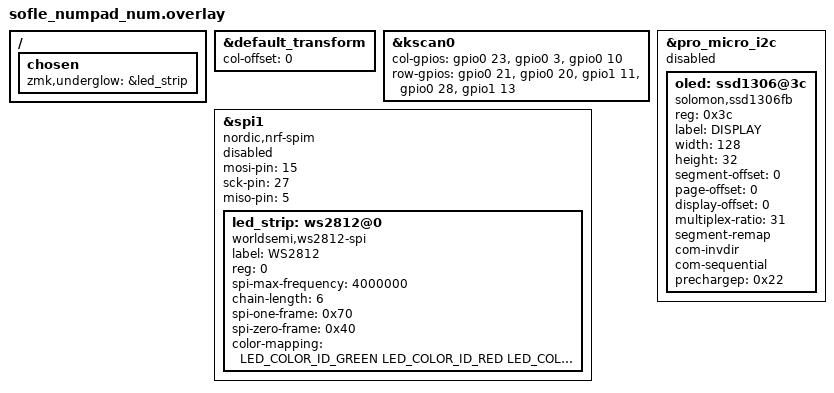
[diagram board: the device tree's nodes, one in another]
/*
 * Copyright (c) 2022 kien242
 *
 * SPDX-License-Identifier: MIT
 */

#include "sofle_numpad.dtsi"
#include <dt-bindings/led/led.h>

/ {
	chosen {
		zmk,underglow = &led_strip;
	};
};

&default_transform {
	col-offset = <0>;
};

&kscan0 {
	col-gpios
		= <&gpio0 23  GPIO_ACTIVE_HIGH>
		, <&gpio0 3 GPIO_ACTIVE_HIGH>
		, <&gpio0 10  GPIO_ACTIVE_HIGH>
		;
		
    row-gpios
        = <&gpio0  21  (GPIO_ACTIVE_HIGH | GPIO_PULL_DOWN)>
        , <&gpio0  20   (GPIO_ACTIVE_HIGH | GPIO_PULL_DOWN)>
        , <&gpio1  11  (GPIO_ACTIVE_HIGH | GPIO_PULL_DOWN)>
        , <&gpio0  28 (GPIO_ACTIVE_HIGH | GPIO_PULL_DOWN)>
        , <&gpio1  13 (GPIO_ACTIVE_HIGH | GPIO_PULL_DOWN)>
        ;
};

&pro_micro_i2c {
    status = "disabled";
    oled: ssd1306@3c {
        compatible = "solomon,ssd1306fb";
        reg = <0x3c>;
        label = "DISPLAY";
        width = <128>;
        height = <32>;
        segment-offset = <0>;
        page-offset = <0>;
        display-offset = <0>;
        multiplex-ratio = <31>;
        segment-remap;
        com-invdir;
        com-sequential;
        prechargep = <0x22>;
    };
};

&spi1 {
  compatible = "nordic,nrf-spim";

  status = "disabled";
  mosi-pin = <15>;
  // Unused pins, needed for SPI definition, but not used by the ws2812 driver itself.
  sck-pin = <27>;
  miso-pin = <5>;

  led_strip: ws2812@0 {
    compatible = "worldsemi,ws2812-spi";
    label = "WS2812";

    /* SPI */
    reg = <0>; /* ignored, but necessary for SPI bindings */
    spi-max-frequency = <4000000>;

    /* WS2812 */
    chain-length = <6>; /* number of LEDs */
    spi-one-frame = <0x70>;
    spi-zero-frame = <0x40>;
    color-mapping = <LED_COLOR_ID_GREEN
                          LED_COLOR_ID_RED
                          LED_COLOR_ID_BLUE>;
  };
};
